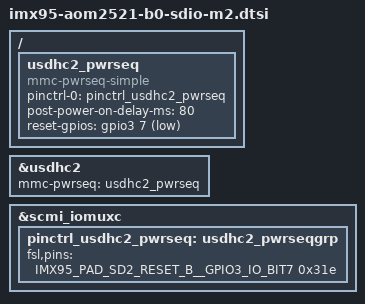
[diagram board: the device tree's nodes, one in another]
/ {
	usdhc2_pwrseq: usdhc2_pwrseq {
		compatible = "mmc-pwrseq-simple";
		pinctrl-names = "default";
                pinctrl-0 = <&pinctrl_usdhc2_pwrseq>;
		post-power-on-delay-ms = <80>;
		reset-gpios =   <&gpio3 7 GPIO_ACTIVE_LOW>;
	};
};

&usdhc2 {
	/delete-property/cd-gpios;
	/delete-property/vmmc-supply;
	mmc-pwrseq = <&usdhc2_pwrseq>;
};

&scmi_iomuxc {
	    pinctrl_usdhc2_pwrseq: usdhc2_pwrseqgrp {
		    fsl,pins = <
			    IMX95_PAD_SD2_RESET_B__GPIO3_IO_BIT7            0x31e
		    >;
	    };
};
